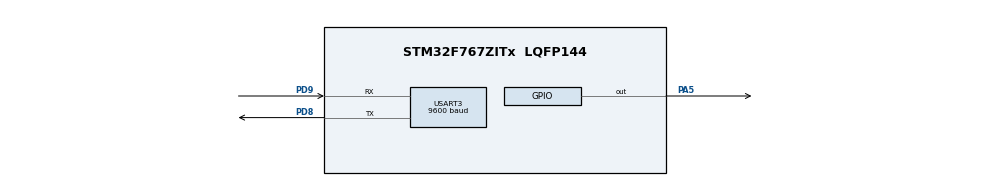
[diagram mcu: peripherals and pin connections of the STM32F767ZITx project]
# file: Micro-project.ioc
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Mcu.Family=STM32F7
Mcu.Name=STM32F767ZITx
Mcu.Package=LQFP144
NVIC.PriorityGroup=NVIC_PRIORITYGROUP_4
NVIC.USART3_IRQn=true\:0\:0\:false\:false\:true\:true\:true\:true
PA5.Signal=GPIO_Output
PD8.Mode=Asynchronous
PD8.Signal=USART3_TX
PD9.Mode=Asynchronous
PD9.Signal=USART3_RX
ProjectManager.HeapSize=0x200
ProjectManager.StackSize=0x400
ProjectManager.TargetToolchain=STM32CubeIDE
RCC.HSE_VALUE=25000000
RCC.HSI_VALUE=16000000
RCC.LSE_VALUE=32768
RCC.USBFreq_Value=96000000
RCC.VCOOutputFreq_Value=192000000
USART3.BaudRate=9600
USART3.Parity=PARITY_NONE
USART3.VirtualMode-Asynchronous=VM_ASYNC
board=custom

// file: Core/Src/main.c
/* USER CODE BEGIN Header */
/**
  ******************************************************************************
  * @file           : main.c
  * @brief          : Main program body
  ******************************************************************************
  * @attention
  *
  * Copyright (c) 2023 STMicroelectronics.
  * All rights reserved.
  *
  * This software is licensed under terms that can be found in the LICENSE file
  * in the root directory of this software component.
  * If no LICENSE file comes with this software, it is provided AS-IS.
  *
  ******************************************************************************
  */
/* USER CODE END Header */
#include "main.h"
#include "usart.h"
#include "gpio.h"

/* USER CODE BEGIN Includes */
#include <stdio.h>
#include "stm32f7xx_hal.h"
#include "buffer.h"
/* USER CODE END Includes */

/* USER CODE BEGIN PD */
#define BUFFER_LENGTH 100
/* USER CODE END PD */

/* USER CODE BEGIN PV */
uint8_t sent_message[BUFFER_LENGTH];
volatile uint16_t message_length;
uint8_t key_pressed;
/* USER CODE END PV */

void SystemClock_Config(void);

/* USER CODE BEGIN 0 */
uint8_t char_is_endmessage(char c)
{
	if (c == '\r' || c == '\n')
	{
		return 1;
	}

	return 0;
}

uint8_t get_char()
{
	uint8_t temp_char;

	temp_char = rx_buffer[rx_busy];
	increase_rx_busy();
	return temp_char;
}

uint16_t pull_message_from_buffer(uint8_t *array)
{
	static uint8_t temp_array[BUFFER_LENGTH];
	static uint16_t idx = 0;
	volatile uint16_t message_length = 0;

	while (rx_has_data() == 1)
	{
		temp_array[idx] = get_char();

		if (char_is_endmessage(temp_array[idx]))
		{
			temp_array[idx] = '\0';

			for (int i = 0; i < idx; i++)
			{
				array[i] = temp_array[i];
			}

			message_length = idx;
			idx = 0;
			return message_length;
		}

		idx++;
		if (idx > BUFFER_LENGTH)
		{
			return 0;
		}
	}

	return 0;
}

/* FRAME CHECK FUNCTIONS */

uint8_t fr_check_length(uint16_t length)
{
	/* Correct frame length between 14 - 526 chars */
	if (length < 14 || length > 526)
	{
		return 0;
	}

	return 1;
}
/* USER CODE END 0 */

int main(void)
{

  /* MCU Configuration--------------------------------------------------------*/

  /* Reset of all peripherals, Initializes the Flash interface and the Systick. */
  HAL_Init();

  /* Configure the system clock */
  SystemClock_Config();

  /* Initialize all configured peripherals */
  MX_GPIO_Init();
  MX_USART3_UART_Init();
  /* USER CODE BEGIN 2 */
  HAL_UART_Receive_IT(&huart3, &key_pressed, 1);
  /* USER CODE END 2 */

  /* Infinite loop */
  while (1)
  {

    /* USER CODE BEGIN 3 */
	  /* Get message when ENTER is pressed and rx_buffer has any data */
	  if (rx_has_data() == 1 && char_is_endmessage(key_pressed))
	  {
		  message_length = pull_message_from_buffer(sent_message);
	  }

	  /* Check frame if the length is correct */
	  if (fr_check_length(message_length))
	  {
		  uint16_t idx = rx_busy - (message_length + 1); /* +1 because of '\r' removal in sent_message */

		  /* Handle buffer wrap-araund */
		  if (idx >= BUFFER_LENGTH)
		  {
			  idx += BUFFER_LENGTH;
		  }

		  /* Transfer message to tx_buffer */
		  while (idx != rx_busy)
		  {
			  tx_buffer[tx_empty] = rx_buffer[idx];
			  increase_tx_empty();
			  idx = (idx + 1) % BUFFER_LENGTH;
		  }

		  /*
		   * Reset message length back to 0 to prevent the code
		   * from re-entering length check indefinitely
		   */

		  message_length = 0;
	  }
  }
  /* USER CODE END 3 */
}

void SystemClock_Config(void)
{
  RCC_OscInitTypeDef RCC_OscInitStruct = {0};
  RCC_ClkInitTypeDef RCC_ClkInitStruct = {0};

  /** Configure the main internal regulator output voltage
  */
  __HAL_RCC_PWR_CLK_ENABLE();
  __HAL_PWR_VOLTAGESCALING_CONFIG(PWR_REGULATOR_VOLTAGE_SCALE3);

  /** Initializes the RCC Oscillators according to the specified parameters
  * in the RCC_OscInitTypeDef structure.
  */
  RCC_OscInitStruct.OscillatorType = RCC_OSCILLATORTYPE_HSI;
  RCC_OscInitStruct.HSIState = RCC_HSI_ON;
  RCC_OscInitStruct.HSICalibrationValue = RCC_HSICALIBRATION_DEFAULT;
  RCC_OscInitStruct.PLL.PLLState = RCC_PLL_NONE;
  if (HAL_RCC_OscConfig(&RCC_OscInitStruct) != HAL_OK)
  {
    Error_Handler();
  }

  /** Initializes the CPU, AHB and APB buses clocks
  */
  RCC_ClkInitStruct.ClockType = RCC_CLOCKTYPE_HCLK|RCC_CLOCKTYPE_SYSCLK
                              |RCC_CLOCKTYPE_PCLK1|RCC_CLOCKTYPE_PCLK2;
  RCC_ClkInitStruct.SYSCLKSource = RCC_SYSCLKSOURCE_HSI;
  RCC_ClkInitStruct.AHBCLKDivider = RCC_SYSCLK_DIV1;
  RCC_ClkInitStruct.APB1CLKDivider = RCC_HCLK_DIV1;
  RCC_ClkInitStruct.APB2CLKDivider = RCC_HCLK_DIV1;

  if (HAL_RCC_ClockConfig(&RCC_ClkInitStruct, FLASH_LATENCY_0) != HAL_OK)
  {
    Error_Handler();
  }
}

/* USER CODE BEGIN 4 */
void HAL_UART_RxCpltCallback(UART_HandleTypeDef *huart)
{
  if (huart->Instance == USART3)
  {
	  HAL_UART_Transmit_IT(huart, &key_pressed, 1);

	  /* Add entered character to the rx array */
	  rx_buffer[rx_empty] = key_pressed;
	  increase_rx_empty();

	  /* Continue listening for input */
	  HAL_UART_Receive_IT(huart, &key_pressed, 1);
  }
}

void HAL_UART_TxCpltCallback(UART_HandleTypeDef *huart)
{
	if (huart->Instance == USART3) {}
}
/* USER CODE END 4 */

void Error_Handler(void)
{
  __disable_irq();
  while (1)
  {
  }
}
